AUTOSAR XML (schema 4-0-3)
package /ComponentTypes
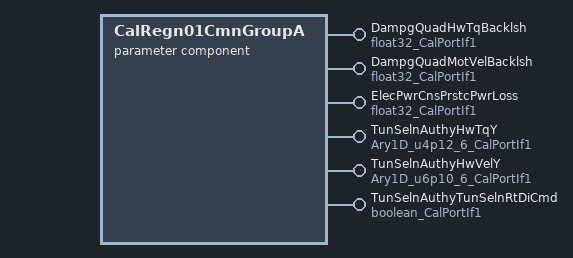
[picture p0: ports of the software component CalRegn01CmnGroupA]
  parameter sw component type CalRegn01CmnGroupA
    6 x provide port:
      DampgQuadHwTqBacklsh: parameter-provide-com-spec{init-value=0, parameter=Val}, provided-interface=float32_CalPortIf1
      DampgQuadMotVelBacklsh: parameter-provide-com-spec{init-value=0, parameter=Val}, provided-interface=float32_CalPortIf1
      ElecPwrCnsPrstcPwrLoss: parameter-provide-com-spec{init-value=10, parameter=Val}, provided-interface=float32_CalPortIf1
      TunSelnAuthyHwTqY: parameter-provide-com-spec{init-value=6 x 20480, parameter=Ary1D}, provided-interface=Ary1D_u4p12_6_CalPortIf1
      TunSelnAuthyHwVelY: parameter-provide-com-spec{init-value=6 x 20480, parameter=Ary1D}, provided-interface=Ary1D_u6p10_6_CalPortIf1
      TunSelnAuthyTunSelnRtDiCmd: parameter-provide-com-spec{init-value=0, parameter=Logl}, provided-interface=boolean_CalPortIf1
